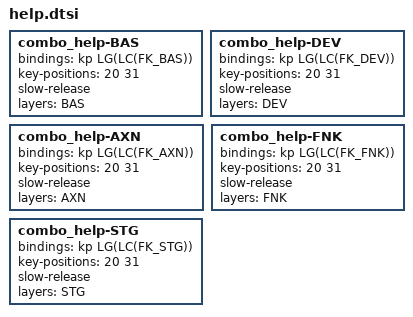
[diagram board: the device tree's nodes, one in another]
/*
 * Copyright (c) 2025 Camilo Martinez (Equiman)
 * SPDX-License-Identifier: MIT
 *
 * Documentation:
 * @see https://zmk.dev/docs/keymaps/combos
 */

combo_help-BAS {
    bindings = <&kp LG(LC(FK_BAS))>;
    key-positions = <20 31>;
    slow-release;
    layers = <BAS>;
};

combo_help-DEV {
    bindings = <&kp LG(LC(FK_DEV))>;
    key-positions = <20 31>;
    slow-release;
    layers = <DEV>;
};

combo_help-AXN {
    bindings = <&kp LG(LC(FK_AXN))>;
    key-positions = <20 31>;
    slow-release;
    layers = <AXN>;
};

combo_help-FNK {
    bindings = <&kp LG(LC(FK_FNK))>;
    key-positions = <20 31>;
    slow-release;
    layers = <FNK>;
};

combo_help-STG {
    bindings = <&kp LG(LC(FK_STG))>;
    key-positions = <20 31>;
    slow-release;
    layers = <STG>;
};
